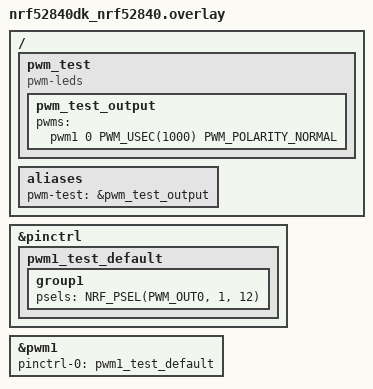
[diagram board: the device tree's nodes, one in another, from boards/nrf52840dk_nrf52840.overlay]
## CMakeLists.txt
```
cmake_minimum_required(VERSION 3.20.0)
find_package(Zephyr REQUIRED HINTS $ENV{ZEPHYR_BASE})
project(nrf52840dk_pwm_test)

target_sources(app PRIVATE src/main.c)
```

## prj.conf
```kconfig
CONFIG_PWM=y
CONFIG_PRINTK=y
```

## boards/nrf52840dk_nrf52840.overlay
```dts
#include <dt-bindings/pwm/pwm.h>

/ {
	pwm_test {
		compatible = "pwm-leds";
		pwm_test_output: pwm_test_output {
			pwms = <&pwm1 0 PWM_USEC(1000) PWM_POLARITY_NORMAL>;
		};
	};

	aliases {
		pwm-test = &pwm_test_output;
	};
};

&pinctrl {
	pwm1_test_default: pwm1_test_default {
		group1 {
			psels = <NRF_PSEL(PWM_OUT0, 1, 12)>;
		};
	};
};

&pwm1 {
	status = "okay";
	pinctrl-0 = <&pwm1_test_default>;
	pinctrl-names = "default";
};
```

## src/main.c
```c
#include <zephyr/device.h>
#include <zephyr/devicetree.h>
#include <zephyr/drivers/pwm.h>
#include <zephyr/kernel.h>
#include <zephyr/sys/printk.h>

static const struct pwm_dt_spec pwm =
	PWM_DT_SPEC_GET(DT_ALIAS(pwm_test));

int main(void)
{
	static const uint8_t duty_percent[] = { 0, 25, 50, 100 };

	if (!pwm_is_ready_dt(&pwm)) {
		printk("PWM device is not ready\n");
		return 0;
	}

	printk("P1.12 PWM test: 1 kHz, 0/25/50/100%%, 5 seconds each\n");

	while (true) {
		for (size_t i = 0; i < ARRAY_SIZE(duty_percent); i++) {
			uint32_t pulse = (pwm.period * duty_percent[i]) / 100U;
			int err = pwm_set_pulse_dt(&pwm, pulse);

			printk("PWM duty: %u%% (err %d)\n", duty_percent[i], err);
			k_sleep(K_SECONDS(5));
		}
	}

	return 0;
}
```
